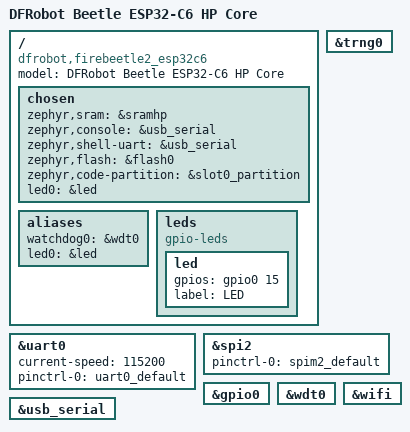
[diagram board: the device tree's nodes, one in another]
/dts-v1/;

#include <espressif/esp32c6/esp32c6_wroom_n4.dtsi>
#include "beetle_esp32c6_hpcore-pinctrl.dtsi"
#include <zephyr/dt-bindings/input/input-event-codes.h>
#include <zephyr/dt-bindings/led/led.h>
#include <espressif/partitions_0x0_default.dtsi>

/ {
	model = "DFRobot Beetle ESP32-C6 HP Core";
	compatible = "dfrobot,firebeetle2_esp32c6";

	chosen {
		zephyr,sram = &sramhp;
		zephyr,console = &usb_serial;
		zephyr,shell-uart = &usb_serial;
		zephyr,flash = &flash0;
		zephyr,code-partition = &slot0_partition;
		led0 = &led;
	};

	aliases {
		watchdog0 = &wdt0;
		led0 = &led;
	};

	leds {
		compatible = "gpio-leds";

		led: led {
			gpios = <&gpio0 15 GPIO_ACTIVE_HIGH>;
			label = "LED";
		};
	};
};

&uart0 {
	status = "okay";
	current-speed = <115200>;
	pinctrl-0 = <&uart0_default>;
	pinctrl-names = "default";
};

/* i2c0 and i2s are left at the SoC default (disabled) on purpose - see the pin notes in
 * beetle_esp32c6_hpcore-pinctrl.dtsi. Their stock pins are taken by carrier hardware on
 * every board that includes this file, so enabling them here would hand a board a
 * peripheral that silently fights the display. A board that really wires one of them up
 * enables it, with its own pinctrl, in its own .dts. */

&trng0 {
	status = "okay";
};

&spi2 {
	#address-cells = <1>;
	#size-cells = <0>;
	status = "okay";
	pinctrl-0 = <&spim2_default>;
	pinctrl-names = "default";
};

&gpio0 {
	status = "okay";
};

&wdt0 {
	status = "okay";
};

&wifi {
	status = "okay";
};

&usb_serial {
	status = "okay";
};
